# PMBUS register map
Vendor: Texas Instruments
Peripheral module from a debugger description file (folder UCD3138R032RSM).
Registers are 32-bit, read-write, no defined reset value unless marked. A register's access mark holds for its fields unless they carry their own. Offsets are as the file gives them; lines under a group give offsets from that group; [hi:lo] are bit positions; {n}, {i} and the like mark numbered series; 'fields as' and 'values as' point back to an identical list; <NAME> marks a mode.

## PMBUS — PMBUS Description
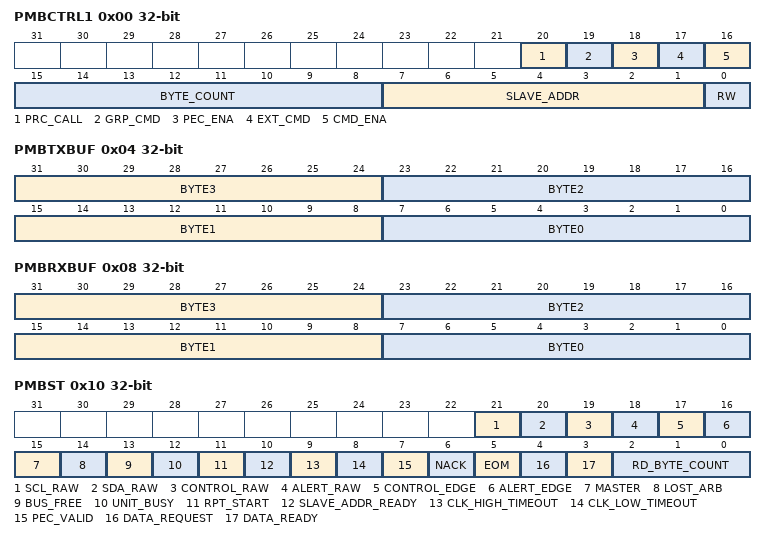
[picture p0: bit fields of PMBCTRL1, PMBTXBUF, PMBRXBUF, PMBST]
0x00 PMBCTRL1 — PMBUS Control Register 1
  [20] PRC_CALL — Master Process Call Message Enable
    1=enabled (Enables transmission of Process Call message); 0=disabled (Default state for all messages besides Process Call message (Default))
  [19] GRP_CMD — Master Group Command Message Enable
    1=enabled (Enables transmission of Group Command message); 0=disabled (Default state for all messages besides Group Command message (Default))
  [18] PEC_ENA — Master PEC Processing Enable
    1=enabled (Enables PEC byte transmission/reception); 0=disabled (Disables PEC processing (Default))
  [17] EXT_CMD — Master Extended Command Code Enable
    1=two_byte (Use 2 byte for Command Code); 0=one_byte (Use 1 byte for Command Code (Default))
  [16] CMD_ENA — Master Command Code Enable
    1=enabled (Enables use of command code on Master initiated messages); 0=disabled (Disables use of command code on Master initiated messages (Default))
  [15:8] BYTE_COUNT — Indicates number of data bytes transmitted in current message. Byte count does not include any device addresses, command words or block lengths in block messages. In block messages, the PMBus Interface automatically inserts the block length into the message based on the byte count setting. The firmware only needs to load the address, command words and data to be transmitted. PMBus Interface supports byte writes up to 255 bytes
  [7:1] SLAVE_ADDR — Specifies the address of the slave to which the current message is directed towards
  [0] RW — Indicates if current Master initiated message is read operation or write operation
    1=read (Message is a read transaction (data from Slave to Master)); 0=write (Message is a write transaction (data from Master to Slave) (Default))
0x04 PMBTXBUF — PMBus Transmit Data Buffer
  [31:24] BYTE3 — Last data byte transmitted from Transmit Data Buffer
  [23:16] BYTE2 — Third data byte transmitted from Transmit Data Buffer
  [15:8] BYTE1 — Second data byte transmitted from Transmit Data Buffer
  [7:0] BYTE0 — First data byte transmitted from Transmit Data Buffer
0x08 PMBRXBUF ro — PMBus Receive Data Register
  fields as PMBTXBUF
0x0C PMBACK — PMBus Acknowledge Register
  [0] ACL — Allows firmware to acknowledge or not acknowledge received data
    1=Acknowledge received data, bit clears upon issue of ACK on PMBus; 0=recieved (NACK received data (Default))
0x10 PMBST ro — PMBus Status Register
  [21] SCL_RAW — PMBus Clock Pin Real Time Status
    1=high (PMBus clock pin observed at logic level high); 0=low (PMBus clock pin observed at logic level low)
  [20] SDA_RAW — PMBus Data Pin Real Time Status
    1=high (PMBus data pin observed at logic level high); 0=low (PMBus data pin observed at logic level low)
  [19] CONTROL_RAW — Control Pin Real Time Status
    1=high (Control pin observed at logic level high); 0=low (Control pin observed at logic level low)
  [18] ALERT_RAW — Control Pin Real Time Status
    1=high (Alert pin observed at logic level high); 0=low (Alert pin observed at logic level low)
  [17] CONTROL_EDGE — Control Edge Detection Status
    1=asserted (Control pin has been asserted by another device on PMBus); 0=not_transitioned (Control pin has not transitioned)
  [16] ALERT_EDGE — Alert Edge Detection Status
    1=asserted (Alert pin has been asserted by another device on PMBus); 0=not_transitioned (Alert pin has not transitioned)
  [15] MASTER — Master Indicator
    1=Master (PMBus Interface in Master Mode); 0=Slave (PMBus Interface in Slave Mode or Idle Mode)
  [14] LOST_ARB — Lost Arbitration Flag
    1=lost (Master has lost arbitration and control of PMBus); 0=attained (Master has attained control of PMBus)
  [13] BUS_FREE — PMBus Free Indicator
    1=new (PMBus available for new message); 0=current (PMBus processing current message)
  [12] UNIT_BUSY — PMBus Busy Indicator
    1=busy (PMBus Interface is busy, processing current message); 0=idle (PMBus Interface is idle, ready to transmit/receive message)
  [11] RPT_START — Repeated Start Flag
    1=Repeated Start condition received by interface; 0=Not_Repeated (No Repeated Start received by interface)
  [10] SLAVE_ADDR_READY — Slave Address Ready
    1=available (Slave address ready to be read from Receive Data Register (Bits 6:0)); 0=Not_available (Indicates no slave address is available for reading)
  [9] CLK_HIGH_TIMEOUT — Clock High Detection Status
    1=Clock High exceeded 50us during message; 0=No Clock High condition detected
  [8] CLK_LOW_TIMEOUT — Clock Low Detection Status
    1=clock_high (Clock low timeout detected, clock held low for greater than 35ms); 0=No_clock_high (No clock low timeout detected)
  [7] PEC_VALID — PEC Valid Indicator
    1=valid (Received PEC is valid); 0=not_valid (Received PEC not valid (if EOM is asserted))
  [6] NACK — Not Acknowledge Flag Status
    1=not_accepted (Receiver has not accepted transmitted data); 0=accepted (Data transmitted has been accepted by receiver)
  [5] EOM — End of Message Indicator
    1=end (End of current message detected); 0=in_progress (Message still in progress or PMBus in idle state)
  [4] DATA_REQUEST — Data Request Flag
    1=additional (PMBus Interface request additional data. PMBus clock stretching enabled to stall bus until firmware provides transmit data); 0=no_addtional (No data needed by PMBus Interface)
  [3] DATA_READY — Data Ready Flag
    1=buffer_full (PMBus Interface read buffer full, firmware required to read data prior to further bus activity. PMBus clock stretching enabled to stall bus until data is read by firmware); 0=not_available (No data available for reading by processor)
  [2:0] RD_BYTE_COUNT — Number of Data Bytes available in Receive Data Register
    4=four_byte (4 byte received. Data located in Receive Data Register, Bits 31-0); 3=three_byte (3 byte received. Data located in Receive Data Register, Bits 23-0); 2=two_byte (2 byte received. Data located in Receive Data Register, Bits 15-0); 1=one_byte (1 byte received. Data located in Receive Data Register, Bits 7-0); 0=no_dat (No received data)
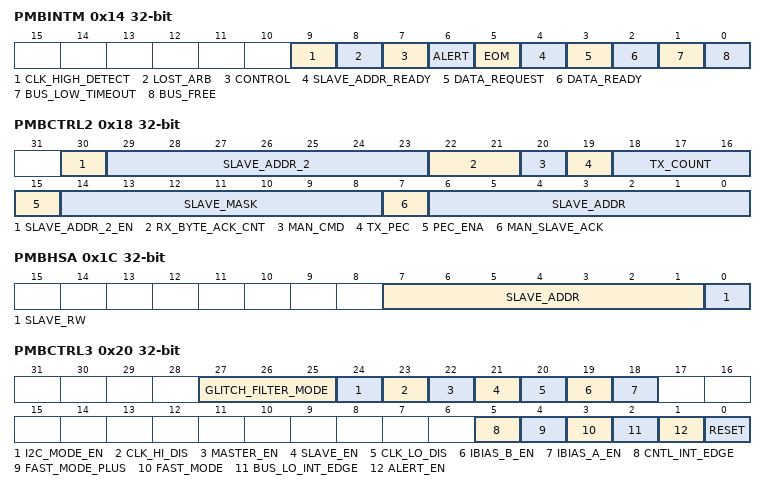
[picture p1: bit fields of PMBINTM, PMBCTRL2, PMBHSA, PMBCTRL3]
0x14 PMBINTM — PMBus Interrupt Mask Register
  [9] CLK_HIGH_DETECT — Clock High Detection Interrupt Mask
    1=Disables interrupt generation for Clock High detection (Default); 0=genrates_interuupt (Generates interrupt if clock high exceeds 50us during message)
  [8] LOST_ARB — Lost Arbitration Interrupt Mask
    1=Disables interrupt generation upon assertion of Lost Arbitration flag (Default); 0=genrates_interuupt (Generates interrupt upon assertion of Lost Arbitration flag)
  [7] CONTROL — Control Detection Interrupt Mask
    1=Disables interrupt generation upon assertion of Control flag (Default); 0=genrates_interuupt (Generates interrupt upon assertion of Control flag)
  [6] ALERT — ALERT Detection Interrupt Mask
    1=Disables interrupt generation upon assertion of ALERT flag (Default); 0=genrates_interuupt (Generates interrupt upon assertion of ALERT flag)
  [5] EOM — End of Message Interrupt Mask
    1=Disables interrupt generation upon assertion of End of Message flag (Default); 0=genrates_interuupt (Generates interrupt upon assertion of End of Message flag)
  [4] SLAVE_ADDR_READY — Slave Address Ready Interrupt Mask
    1=Disables interrupt generation upon assertion of Slave Address Ready flag (Default); 0=genrates_interuupt (Generates interrupt upon assertion of Slave Address Ready flag)
  [3] DATA_REQUEST — Data Request Interrupt Mask
    1=Disables interrupt generation upon assertion of Data Request flag (Default); 0=genrates_interuupt (Generates interrupt upon assertion of Data Request flag)
  [2] DATA_READY — Data Ready Interrupt Mask
    1=Disables interrupt generation upon assertion of Data Ready flag (Default); 0=genrates_interuupt (Generates interrupt upon assertion of Data Ready flag)
  [1] BUS_LOW_TIMEOUT — Clock Low Timeout Interrupt Mask
    1=Disables interrupt generation upon assertion of Clock Low Timeout flag (Default); 0=genrates_interuupt (Generates interrupt upon assertion of Clock Low Timeout flag)
  [0] BUS_FREE — Bus Free Interrupt Mask
    1=Disables interrupt generation upon assertion of Bus Free flag (Default); 0=genrates_interuupt (Generates interrupt upon assertion of Bus Free flag)
0x18 PMBCTRL2 — PMBus Control Register 2
  [30] SLAVE_ADDR_2_EN — Enable auto detection of the 2nd slave address
    1=disabled (2nd slave address enabled); 0=enabled (2nd slave address disabled (default))
  [29:23] SLAVE_ADDR_2 — Configures the second device address of the slave. Used in automatic slave address acknowledge mode (default mode).
  [22:21] RX_BYTE_ACK_CNT — Configures number of data bytes to automatically acknowledge when receiving data in slave mode
    3=four_bytes (4 bytes received by slave. Hardware automatically acknowledges the first 3 received bytes. Firmware is required to manually acknowledge after the fourth received byte); 2=three_bytes (3 bytes received by slave. Hardware automatically acknowledges the first 2 received bytes. Firmware is required to manually acknowledge after the third received byte); 1=two_bytes (2 bytes received by slave. Hardware automatically acknowledges the first received byte. Firmware is required to manually acknowledge after the second received byte); 0=one_byte (1 byte received by slave. Firmware is required to manually acknowledge every received byte)
  [20] MAN_CMD — Manual Command Acknowledgement Mode
    1=request_flag (Data Request flag generated after receipt of command code, firmware required to issue ACK to continue message); 0=acknowledges (Slave automatically acknowledges received command code (Default))
  [19] TX_PEC — Asserted when the slave needs to send a PEC byte at end of message. PMBus Interface will transmit the calculated PEC byte after transmitting the number of data bytes indicated by TX Byte Cnt(Bits 19:17)
    1=PEC (PEC byte transmitted at end of current message); 0=No PEC byte transmitted (Default)
  [18:16] TX_COUNT — Number of valid bytes in Transmit Data Register
    4=Four bytes valid, Bytes #0-3 (Bits 31:0 of Receive Data Register); 3=Three bytes valid, Bytes #0-2 (Bits 23:0 of Receive Data Register); 2=two (Two bytes valid, Bytes #0 and #1 (Bits 15:0 of Receive Data Register)); 1=one (One byte valid, Byte #0 (Bits 7:0 of Receive Data Register)); 0=No bytes valid (Default)
  [15] PEC_ENA — PEC Processing Enable
    1=enable (PEC processing enabled); 0=diabled (PEC processing disabled (Default))
  [14:8] SLAVE_MASK — Used in address detection, the slave mask enables acknowledgement of multiple device addresses by the slave. Writing a ‘0’ to a bit within the slave mask enables the corresponding bit in the slave address to be either ‘1’ or ‘0’ and still allow for a match. Writing a ‘0’ to all bits in the mask enables the PMBus Interface to acknowledge any device address. Upon power-up, the slave mask defaults to 7Fh, indicating the slave will only acknowledge the address programmed into the Slave Address (Bits 6-0).
  [7] MAN_SLAVE_ACK — Manual Slave Address Acknowledgement Mode
    1=Enables the Manual Slave Address Acknowledgement Mode. Firmware is required to read received address and acknowledge on every message; 0=diabled (Slave automatically acknowledges device address specified in SLAVE_ADDR, Also uses SLAVE_ADDR_2 if present and enabled. (Default))
  [6:0] SLAVE_ADDR — Configures the current device address of the slave. Used in automatic slave address acknowledge mode (default mode). The PMBus Interface will compare the received device address with the value stored in the Slave Address bits and the mask configured in the Slave Mask bits. If matching, the slave will acknowledge the device address
0x1C PMBHSA ro — PMBus Hold Slave Address Register
  [7:1] SLAVE_ADDR — Enable auto detection of the 2nd slave address
  [0] SLAVE_RW — Stored device address acknowledged by the slave
    1=Read Access; 0=Write Access
0x20 PMBCTRL3 access per field — PMBus Hold Slave Address Register
  [27:25] GLITCH_FILTER_MODE rw — Selects the glitch filter mode enabled
    7=Illegal_1 (Illegal Value); 6=_400ns_glitch_filter; 5=_200ns_glitch_filter; 4=_100ns_glitch_filter; 3=Illegal Value; 2=glitch_filter_disabled; 1=_2x_PMBCLK_glitch_filter; 0=_50ns_glitch_filter
  [24] I2C_MODE_EN rw — I2C Mode Enable - Utilized for Master mode only.The only effect of I2C_MODE_EN is to remove the automatic insertion of number of bytes in block writes in master mode
    1=enabled (I2C Mode Enabled); 0=disabled (I2C Mode Disabled (Default))
  [23] CLK_HI_DIS rw — Clock High Timeout Disable
    1=enabled (Clock High Timeout Disabled); 0=disabled (Clock High Timeout Disabled (Default))
  [22] MASTER_EN rw — PMBus Master Enable
    1=enabled (Enables PMBus Master capability); 0=disabled (Disables PMBus Master capability (Default))
  [21] SLAVE_EN rw — PMBus SLAVE Enable
    1=enabled (Enables PMBus SLAVE capability); 0=disabled (Disables PMBus SLAVE capability (Default))
  [20] CLK_LO_DIS rw — Clock Low Timeout Disable
    1=disabled (Clock Low Timeout Disabled); 0=enabled (Clock Low Timeout Enabled (Default))
  [19] IBIAS_B_EN rw — PMBus Current Source B Control
    1=enabled (Enables Current Source for PMBUS address detection thru ADC); 0=disabled (Disables Current Source for PMBUS address detection thru ADC (Default))
  [18] IBIAS_A_EN rw — PMBus Current Source A Control
    values as IBIAS_B_EN
  [5] CNTL_INT_EDGE rw — Control Interrupt Edge Select
    1=rising_edge (Interrupt generated on rising edge of Control); 0=falling_edge (Interrupt generated on falling edge of Control (Default))
  [4] FAST_MODE_PLUS rw — Fast Mode Plus Enable
    1=Fast Mode Plus enabled (1MHz operation on PMBus); 0=Standard 100 KHz mode enabled (Default)
  [3] FAST_MODE rw — Fast Mode Enable
    1=Fast Mode Plus enabled (400KHz operation on PMBus); 0=Standard 100 KHz mode enabled (Default)
  [2] BUS_LO_INT_EDGE rw — Clock Low Timeout Interrupt Edge Select
    1=falling_edge (Interrupt generated on falling edge of clock low timeout); 0=rising_edge (Interrupt generated on rising edge of clock low timeout (Default))
  [1] ALERT_EN rw — Slave Alert Enable
    1=driven (PMBus Alert driven low by slave); 0=not_driven (PMBus Alert is not driven by slave, pulled up high on PMBus (Default))
  [0] RESET rw — PMBus Interface Synchronous Reset
    1=reset (Control state machines are reset to initial states); 0=not_reset (No reset of internal state machines (Default))
0x80 PMB_DBG ro — PMBus Debug Register
  [4:0] PMBus_STATE — Mentions the current PMBus State
